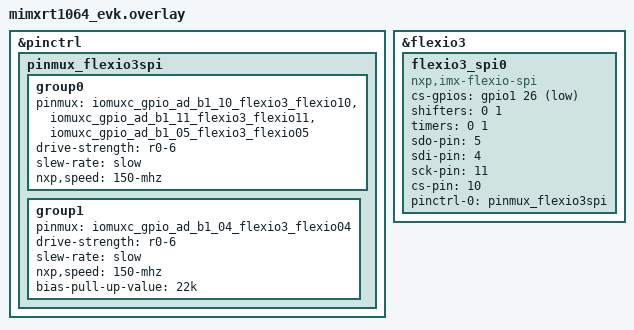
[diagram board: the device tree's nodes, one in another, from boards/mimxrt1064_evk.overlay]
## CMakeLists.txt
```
# Copyright (c) 2022, STRIM, ALC
# SPDX-License-Identifier: Apache-2.0

cmake_minimum_required(VERSION 3.20.0)
find_package(Zephyr REQUIRED HINTS $ENV{ZEPHYR_BASE})
project(mcux_flexio_spi)

target_sources(app PRIVATE
    src/main.c
    )
```

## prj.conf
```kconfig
CONFIG_SPI=y
CONFIG_SPI_MCUX_FLEXIO=y
```

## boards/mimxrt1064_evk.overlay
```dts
/*
* Copyright (c) 2022, STRIM, ALC
* SPDX-License-Identifier: Apache-2.0
*/

&pinctrl {
	pinmux_flexio3spi: pinmux_flexio3spi {
		group0 {
			pinmux = <&iomuxc_gpio_ad_b1_10_flexio3_flexio10>,
				// <&iomuxc_gpio_ad_b1_10_gpio1_io26>,
				<&iomuxc_gpio_ad_b1_11_flexio3_flexio11>,
				<&iomuxc_gpio_ad_b1_05_flexio3_flexio05>;
			drive-strength = "r0-6";
			slew-rate = "slow";
			nxp,speed = "150-mhz";
		};
		group1 {
			pinmux = <&iomuxc_gpio_ad_b1_04_flexio3_flexio04>;
			drive-strength = "r0-6";
			slew-rate = "slow";
			nxp,speed = "150-mhz";
			bias-pull-up-value = "22k";
		};
	};
};

&flexio3 {
	status = "okay";
	flexio3_spi0: flexio3_spi0 {
		compatible = "nxp,imx-flexio-spi";
		status = "okay";
		#address-cells = <1>;
		#size-cells = <0>;
		cs-gpios = <&gpio1 26 GPIO_ACTIVE_LOW>;
		shifters = <0 1>;
		timers   = <0 1>;
		sdo-pin = <5>;
		sdi-pin = <4>; 
		sck-pin = <11>;
		cs-pin  = <10>; /* unused */
		pinctrl-0 = <&pinmux_flexio3spi>;
		pinctrl-names = "default";
	};
};
```

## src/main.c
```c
/*
* Copyright (c) 2022, STRIM, ALC
* SPDX-License-Identifier: Apache-2.0
*/

#include <zephyr/kernel.h>
#include <zephyr/drivers/spi.h>
#include <zephyr/device.h>
#include <zephyr/devicetree.h>
#include <stdio.h>
#include <string.h>


void main(void) 
{
	printf("\nFLEXIO SPI testing\n");
	printf(  "==================\n");
	const struct device *spi_dev = DEVICE_DT_GET(DT_NODELABEL(flexio3_spi0));

	if (!device_is_ready(spi_dev)) {
		printk("spi device not ready.\n");
	    return;
	}

	printf("device %s is ready", spi_dev->name);

	static const struct spi_cs_control cs = {
		.gpio = GPIO_DT_SPEC_GET_BY_IDX(DT_NODELABEL(flexio3_spi0), cs_gpios, 0)
	};
	const static struct spi_dt_spec bus = {
		.bus = DEVICE_DT_GET(DT_NODELABEL(flexio3_spi0)),
		.config = {
			.frequency = 1000000,
			.operation = SPI_OP_MODE_MASTER | SPI_MODE_CPOL | SPI_MODE_CPHA | SPI_TRANSFER_LSB | SPI_WORD_SET(8),
			.slave = 0,
			.cs = &cs
		}
	};

	if (!spi_is_ready(&bus)) {
		printk("spi device not ready.\n");
	    return;
	}

	while (true) {
		uint8_t buffer_tx[4] = { 0x12, 0xF1, 0x0, 0x0 };
		uint8_t buffer_rx[4] = { 0x0, 0x0, 0xFF, 0xFF };

		const struct spi_buf tx_buf[2] = {
			{
				.buf = buffer_tx,
				.len = 1
			},
			{
				.buf = &buffer_tx[1],
				.len = 3,
			}
		};
		const struct spi_buf_set tx = {
			.buffers = tx_buf,
			.count = ARRAY_SIZE(tx_buf),
		};

		const struct spi_buf rx_buf[2] = {
			{
				.buf = NULL,
				.len = 1
			},
			{
				.buf = buffer_rx,
				.len = 3,
			}
		};
		const struct spi_buf_set rx = {
			.buffers = rx_buf,
			.count = ARRAY_SIZE(rx_buf),
		};

		int ret = spi_transceive_dt(&bus, &tx, &rx);
		if (ret) {
		 	k_sleep(K_MSEC(2000));
		}
	}
}
```
